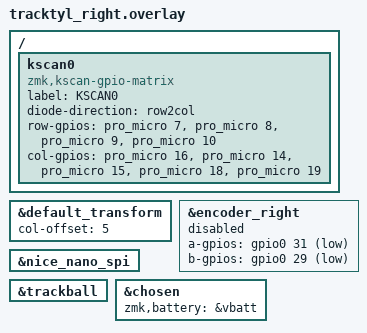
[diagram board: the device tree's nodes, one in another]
#include "tracktyl.dtsi"

&default_transform { // The matrix transform for this board is 5 columns over because the left half is 5 columns wide according to the matrix.
    col-offset = <5>;
};

/ {
    kscan0: kscan0 {
        compatible = "zmk,kscan-gpio-matrix";
        label = "KSCAN0";

		diode-direction = "row2col"; // amoeba royale needs to do row2col

		row-gpios
			= <&pro_micro 7 GPIO_ACTIVE_HIGH>
            , <&pro_micro 8 GPIO_ACTIVE_HIGH>
            , <&pro_micro 9 GPIO_ACTIVE_HIGH>
			, <&pro_micro 10 GPIO_ACTIVE_HIGH>
            ;
            col-gpios
            = <&pro_micro 16 (GPIO_ACTIVE_HIGH | GPIO_PULL_DOWN)>
            , <&pro_micro 14 (GPIO_ACTIVE_HIGH | GPIO_PULL_DOWN)>
            , <&pro_micro 15 (GPIO_ACTIVE_HIGH | GPIO_PULL_DOWN)>
            , <&pro_micro 18 (GPIO_ACTIVE_HIGH | GPIO_PULL_DOWN)>
            , <&pro_micro 19 (GPIO_ACTIVE_HIGH | GPIO_PULL_DOWN)>
            ;
	};
};

/* Enable the right encoder and define its pins */
&encoder_right {
    status = "disabled";  // disable encoders until further hardware impl
    a-gpios = <&gpio0 31 (GPIO_ACTIVE_LOW | GPIO_PULL_UP)>;
    b-gpios = <&gpio0 29 (GPIO_ACTIVE_LOW | GPIO_PULL_UP)>;
};

&nice_nano_spi {
    status = "okay";
};

&trackball {
    status = "okay";
};

&chosen {
    zmk,battery = &vbatt;
};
